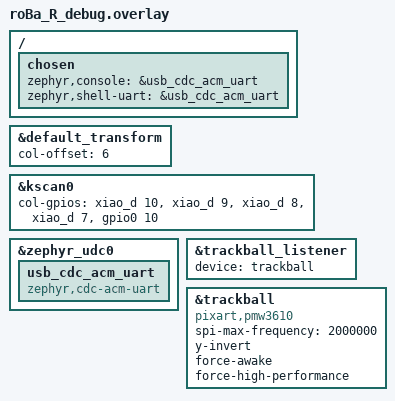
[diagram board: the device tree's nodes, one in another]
#include "roBa.dtsi"
#include "roBa_R_trackball.dtsi"

&default_transform {
    col-offset = <6>;
};

&kscan0 {
    col-gpios
        = <&xiao_d 10 GPIO_ACTIVE_HIGH>
        , <&xiao_d 9 GPIO_ACTIVE_HIGH>
        , <&xiao_d 8 GPIO_ACTIVE_HIGH>
        , <&xiao_d 7 GPIO_ACTIVE_HIGH>
        , <&gpio0 10 GPIO_ACTIVE_HIGH>
        ;
};

/ {
    chosen {
        zephyr,console = &usb_cdc_acm_uart;
        zephyr,shell-uart = &usb_cdc_acm_uart;
    };
};

&zephyr_udc0 {
    usb_cdc_acm_uart: usb_cdc_acm_uart {
        compatible = "zephyr,cdc-acm-uart";
    };
};

&trackball_listener {
    status = "okay";
    device = <&trackball>;
};

&trackball {
    compatible = "pixart,pmw3610";
    spi-max-frequency = <2000000>;
    y-invert;
    force-awake;
    force-high-performance;
    /delete-property/ invert-y;
};
